# ADuCM350 register map
Vendor: Analog Devices; Series: ARMCM3; File version: 0.1
CPU: CM3 r2p1, little endian, no MPU, no FPU, 3 interrupt priority bits
Registers are 16-bit, access not given, no defined reset value unless marked. A register's access mark holds for its fields unless they carry their own. Offsets are from the block's base; [hi:lo] are bit positions.

## WUT — Wake-up timer
Base 0x40002500
0x00 REG_WUT_T2VAL0 — WUT Current count value - LS halfword.
  [15:0] VALUE
0x04 REG_WUT_T2VAL1 — WUT Current count value - MS halfword
  [15:0] VALUE
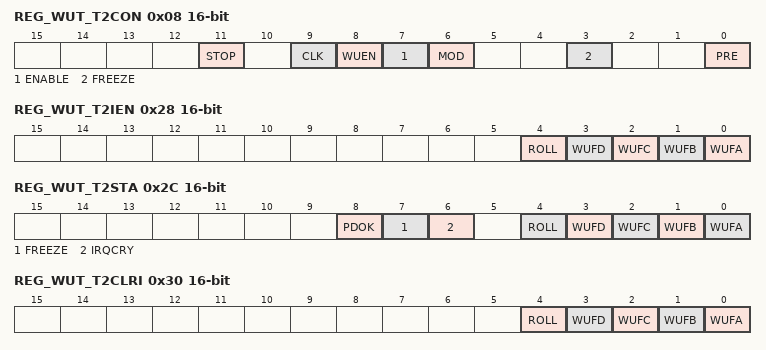
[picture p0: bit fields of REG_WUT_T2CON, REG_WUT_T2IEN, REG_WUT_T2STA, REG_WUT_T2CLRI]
0x08 REG_WUT_T2CON — WUT Control
  [11] STOP — Disables updating field A register T2WUFA
  [9] CLK — Clock select
  [8] WUEN — Wakeup enable
  [7] ENABLE — Timer enable
  [6] MOD — Timer mode
  [3] FREEZE — Freeze enable
  [0] PRE — Prescaler
0x0C REG_WUT_T2INC — WUT 12-bit interval for wakeup field A
  [0] INTERVAL — Interval for wakeup field A
0x10 REG_WUT_T2WUFB0 — WUT Wakeup field B - LS halfword
  [15:0] VALUE
0x14 REG_WUT_T2WUFB1 — WUT Wakeup field B - MS halfword
  [15:0] VALUE
0x18 REG_WUT_T2WUFC0 — WUT Wakeup field C - LS halfword
  [15:0] VALUE
0x1C REG_WUT_T2WUFC1 — WUT Wakeup field C - MS halfword
  [15:0] VALUE
0x20 REG_WUT_T2WUFD0 — WUT Wakeup field D - LS halfword
  [15:0] VALUE
0x24 REG_WUT_T2WUFD1 — WUT Wakeup field D - MS halfword
  [15:0] VALUE
0x28 REG_WUT_T2IEN — WUT Interrupt enable
  [4] ROLL — Rollover interrupt enable
  [3] WUFD — T2WUFD interrupt enable
  [2] WUFC — T2WUFC interrupt enable
  [1] WUFB — T2WUFB interrupt enable
  [0] WUFA — T2WUFA interrupt enable
0x2C REG_WUT_T2STA — WUT Status
  [8] PDOK — Enable bit synchronized
  [7] FREEZE — Timer value freeze
  [6] IRQCRY — Wakeup status to powerdown
  [4] ROLL — Rollover interrupt flag
  [3] WUFD — T2WUFD interrupt flag
  [2] WUFC — T2WUFC interrupt flag
  [1] WUFB — T2WUFB interrupt flag
  [0] WUFA — T2WUFA interrupt flag
0x30 REG_WUT_T2CLRI — WUT Clear interrupt register
  [4] ROLL — Rollover interrupt clear
  [3] WUFD — T2WUFD interrupt clear
  [2] WUFC — T2WUFC interrupt clear
  [1] WUFB — T2WUFB interrupt clear
  [0] WUFA — T2WUFA interrupt clear
0x34 REG_WUT_WUTVAL_LOW — WUT Unsynchronized lower 16 bits of WU Timer counter value.
  [15:0] VALUE
0x38 REG_WUT_WUTVAL_HIGH — WUT Unsynchronized upper 16 bits of WU Timer counter value.
  [15:0] VALUE
0x3C REG_WUT_T2WUFA0 — WUT Wakeup field A - LS halfword
  [15:0] VALUE
0x40 REG_WUT_T2WUFA1 — WUT Wakeup field A - MS halfword
  [15:0] VALUE

## WDT — WatchDog Timer
Base 0x40002580
0x00 REG_WDT_T3LD — WDT Load value
  [15:0] VALUE
0x04 REG_WDT_T3VAL — WDT Current count value
  [15:0] VALUE
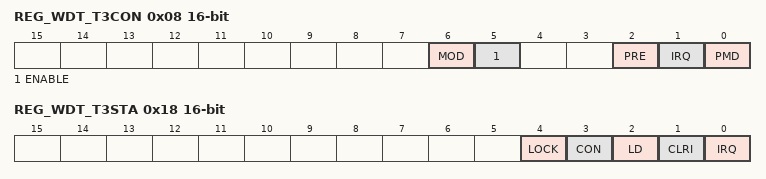
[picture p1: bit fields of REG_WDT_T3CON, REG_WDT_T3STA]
0x08 REG_WDT_T3CON — WDT Control
  [6] MOD — Timer mode
  [5] ENABLE — Timer enable
  [2] PRE — Prescaler
  [1] IRQ — Timer interrupt
  [0] PMD — Power Mode Disable
0x0C REG_WDT_T3CLRI — WDT Clear interrupt register
  [15:0] VALUE
0x18 REG_WDT_T3STA — WDT Status
  [4] LOCK — Lock status bit
  [3] CON — T3CON write sync in progress
  [2] LD — T3LD write sync in progress
  [1] CLRI — T3CLRI write sync in progress
  [0] IRQ — WDT Interrupt

## RTC — RealTimeClock
Base 0x40002600
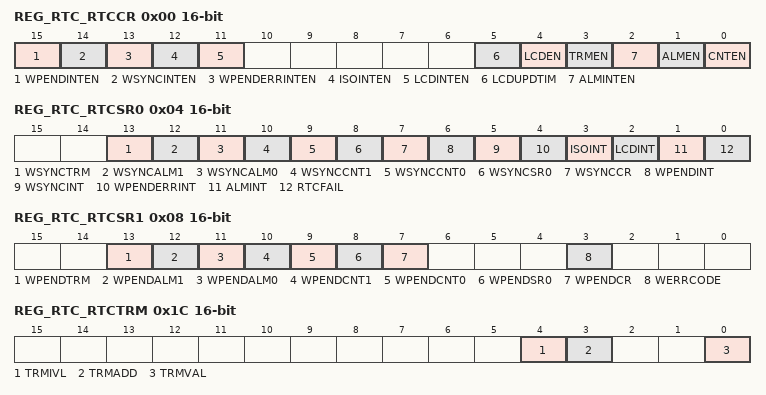
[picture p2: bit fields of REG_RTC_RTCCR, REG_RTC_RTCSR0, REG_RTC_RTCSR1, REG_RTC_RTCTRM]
0x00 REG_RTC_RTCCR — RTC RTC Control
  [15] WPENDINTEN — Enable WPENDINT-sourced interrupts to the CPU
  [14] WSYNCINTEN — Enable WSYNCINT-sourced interrupts to the CPU
  [13] WPENDERRINTEN — Enable WPENDERRINT-sourced interrupts to the CPU when an RTC register-write pending error occurs
  [12] ISOINTEN — Enable ISOINT-sourced interrupts to the CPU when isolation of the RTC power domain is activated and subsequently de-activated
  [11] LCDINTEN — Enable LCDINT-sourced LCD update interrupts to the CPU
  [5] LCDUPDTIM — LCD update time in seconds beyond a one-minute boundary
  [4] LCDEN — Enable RTC determination of when an LCD minute display update should occur
  [3] TRMEN — Enable RTC digital trimming
  [2] ALMINTEN — Enable ALMINT-sourced alarm interrupts to the CPU
  [1] ALMEN — Enable the RTC alarm operation
  [0] CNTEN — Global enable for the RTC
0x04 REG_RTC_RTCSR0 — RTC RTC Status 0
  [13] WSYNCTRM — Synchronisation status of posted writes to RTCTRM
  [12] WSYNCALM1 — Synchronisation status of posted writes to RTCALM1
  [11] WSYNCALM0 — Synchronisation status of posted writes to RTCALM0
  [10] WSYNCCNT1 — Synchronisation status of posted writes to RTCCNT1
  [9] WSYNCCNT0 — Synchronisation status of posted writes to RTCCNT0
  [8] WSYNCSR0 — Synchronisation status of posted clearances to interrupt sources in RTCSR0
  [7] WSYNCCR — Synchronisation status of posted writes to RTCCR
  [6] WPENDINT — Write pending interrupt
  [5] WSYNCINT — Write synchronisation interrupt
  [4] WPENDERRINT — Write pending error interrupt source
  [3] ISOINT — RTC power-domain isolation interrupt source
  [2] LCDINT — LCD update interrupt source
  [1] ALMINT — Alarm interrupt source
  [0] RTCFAIL — RTC failure interrupt source
0x08 REG_RTC_RTCSR1 — RTC RTC Status 1
  [13] WPENDTRM — Pending status of posted writes to RTCTRM
  [12] WPENDALM1 — Pending status of posted writes to RTCALM1
  [11] WPENDALM0 — Pending status of posted writes to RTCALM0
  [10] WPENDCNT1 — Pending status of posted writes to RTCCNT1
  [9] WPENDCNT0 — Pending status of posted writes to RTCCNT0
  [8] WPENDSR0 — Pending status of posted clearances of interrupt sources in RTCSR0
  [7] WPENDCR — Pending status of posted writes to RTCCR
  [3] WERRCODE — Identifier for the source of a write synchronisation error
0x0C REG_RTC_RTCCNT0 — RTC RTC Count 0
  [15:0] VALUE
0x10 REG_RTC_RTCCNT1 — RTC RTC Count 1
  [15:0] VALUE
0x14 REG_RTC_RTCALM0 — RTC RTC Alarm 0
  [15:0] VALUE
0x18 REG_RTC_RTCALM1 — RTC RTC Alarm 1
  [15:0] VALUE
0x1C REG_RTC_RTCTRM — RTC RTC Trim
  [4] TRMIVL — Trim interval in units of seconds
  [3] TRMADD — Trim polarity
  [0] TRMVAL — Trim value in whole seconds to be added or subtracted from the RTC count at the end of a periodic interval
0x20 REG_RTC_RTCGWY — RTC RTC Gateway
  [15:0] VALUE
